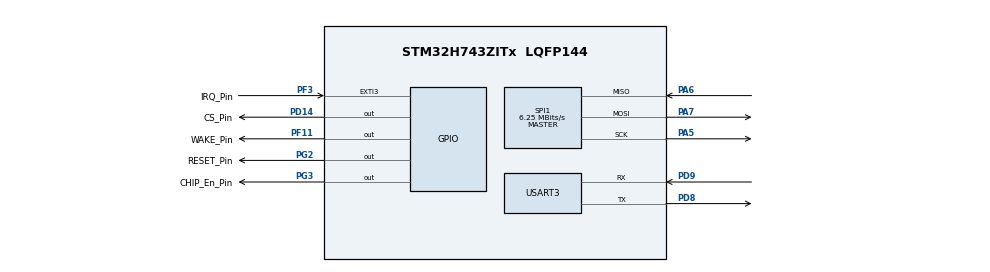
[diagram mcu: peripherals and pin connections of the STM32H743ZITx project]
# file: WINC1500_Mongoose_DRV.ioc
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CORTEX_M7.default_mode_Activation=1
Mcu.Family=STM32H7
Mcu.Name=STM32H743ZITx
Mcu.Package=LQFP144
NVIC.EXTI3_IRQn=true\:0\:0\:false\:false\:true\:true\:true\:true
NVIC.PriorityGroup=NVIC_PRIORITYGROUP_4
NVIC.TIM6_DAC_IRQn=true\:15\:0\:false\:false\:true\:false\:true\:true
NVIC.TimeBase=TIM6_DAC_IRQn
NVIC.TimeBaseIP=TIM6
PA5.GPIO_PuPd=GPIO_PULLUP
PA5.Mode=Full_Duplex_Master
PA5.Signal=SPI1_SCK
PA6.GPIO_PuPd=GPIO_PULLUP
PA6.Mode=Full_Duplex_Master
PA6.Signal=SPI1_MISO
PA7.GPIO_PuPd=GPIO_PULLUP
PA7.Mode=Full_Duplex_Master
PA7.Signal=SPI1_MOSI
PD14.GPIO_Label=CS_Pin
PD14.GPIO_PuPd=GPIO_PULLUP
PD14.Signal=GPIO_Output
PD8.Mode=Asynchronous
PD8.Signal=USART3_TX
PD9.Mode=Asynchronous
PD9.Signal=USART3_RX
PF11.GPIO_Label=WAKE_Pin
PF11.Signal=GPIO_Output
PF3.GPIO_Label=IRQ_Pin
PF3.GPIO_PuPd=GPIO_PULLUP
PF3.Signal=GPXTI3
PG2.GPIO_Label=RESET_Pin
PG2.GPIO_ModeDefaultOutputPP=GPIO_MODE_OUTPUT_PP
PG2.GPIO_PuPd=GPIO_PULLUP
PG2.Signal=GPIO_Output
PG3.GPIO_Label=CHIP_En_Pin
PG3.GPIO_PuPd=GPIO_PULLUP
PG3.Signal=GPIO_Output
ProjectManager.HeapSize=0x600
ProjectManager.StackSize=0x800
ProjectManager.TargetToolchain=STM32CubeIDE
RCC.ADCFreq_Value=129000000
RCC.APB1Freq_Value=100000000
RCC.APB2Freq_Value=100000000
RCC.APB3Freq_Value=100000000
RCC.APB4Freq_Value=100000000
RCC.CortexFreq_Value=400000000
RCC.D1PPRE=RCC_APB3_DIV2
RCC.D2PPRE1=RCC_APB1_DIV2
RCC.D2PPRE2=RCC_APB2_DIV2
RCC.D3PPRE=RCC_APB4_DIV2
RCC.DIVM1=4
RCC.DIVN1=50
RCC.DIVQ1=4
RCC.HCLKFreq_Value=200000000
RCC.HPRE=RCC_HCLK_DIV2
RCC.PLL2FRACN=0
RCC.PLL3FRACN=0
RCC.PLLFRACN=0
RCC.SYSCLKFreq_VALUE=400000000
RCC.SYSCLKSource=RCC_SYSCLKSOURCE_PLLCLK
RCC.USBFreq_Value=200000000
SPI1.BaudRatePrescaler=SPI_BAUDRATEPRESCALER_32
SPI1.CalculateBaudRate=6.25 MBits/s
SPI1.Direction=SPI_DIRECTION_2LINES
SPI1.Mode=SPI_MODE_MASTER
SPI1.VirtualType=VM_MASTER
USART3.VirtualMode-Asynchronous=VM_ASYNC
VP_MEMORYMAP_VS_MEMORYMAP.Mode=CurAppReg
VP_SYS_VS_tim6.Mode=TIM6
board=custom

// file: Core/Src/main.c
/* USER CODE BEGIN Header */
/**
  ******************************************************************************
  * @file           : main.c
  * @brief          : Main program body
  ******************************************************************************
  */
/* USER CODE END Header */

#include "main.h"
#include "spi.h"
#include "usart.h"
#include "gpio.h"

/* USER CODE BEGIN Includes */
#include <stdbool.h>
#include <string.h>
#include "m2m_wifi.h"
#include "conf_winc.h"
#include "socket.h"
#include "mongoose.h"
#include "winc_if.h"

/* USER CODE END Includes */

// Implementazione di gettimeofday
int _gettimeofday(struct timeval *tv, void *tzp) {
    (void)tzp;
    if (tv) {
        uint32_t tick = HAL_GetTick();
        tv->tv_sec = tick / 1000;
        tv->tv_usec = (tick % 1000) * 1000;
    }
    return 0;
}

void SystemClock_Config(void);
static void MPU_Config(void);
/* USER CODE BEGIN PFP */

static struct mg_mgr mgr;

// AGGIUNGI: definisci mg_millis come weak per evitare conflitti
__attribute__((weak)) uint64_t mg_millis(void) {
    return (uint64_t)HAL_GetTick();
}

#ifdef __GNUC__
#define PUTCHAR_PROTOTYPE int __io_putchar(int ch)
#else
#define PUTCHAR_PROTOTYPE int fputc(int ch, FILE *f)
#endif

extern void isr(void);

void HAL_GPIO_EXTI_Callback(uint16_t GPIO_Pin) {
    if (GPIO_Pin == CONF_WINC_SPI_INT_PIN) {
        isr();
    }
}

static void wifi_cb(uint8_t u8MsgType, void *pvMsg) {
    switch (u8MsgType) {
        case M2M_WIFI_RESP_CON_STATE_CHANGED: {
            tstrM2mWifiStateChanged *pstrWifiState = (tstrM2mWifiStateChanged *)pvMsg;
            if (pstrWifiState->u8CurrState == M2M_WIFI_CONNECTED) {
                printf("WiFi: Station connected\n");
            } else if (pstrWifiState->u8CurrState == M2M_WIFI_DISCONNECTED) {
                printf("WiFi: Station disconnected\n");
            }
            break;
        }
        case M2M_WIFI_REQ_DHCP_CONF: {
            uint8_t *pu8IPAddress = (uint8_t *)pvMsg;
            printf("WiFi: DHCP configured - IP: %u.%u.%u.%u\n",
                   pu8IPAddress[0], pu8IPAddress[1], pu8IPAddress[2], pu8IPAddress[3]);
            break;
        }
        default:
            break;
    }
}

PUTCHAR_PROTOTYPE {
    HAL_UART_Transmit(&huart3, (uint8_t *)&ch, 1, 0xFFFF);
    return ch;
}

int main(void) {
    tstrWifiInitParam param;
    tstrM2MAPConfig strM2MAPConfig;
    int8_t ret;

    // Inizializzazione HAL
    MPU_Config();
    HAL_Init();
    SystemClock_Config();
    MX_GPIO_Init();
    MX_SPI1_Init();
    MX_USART3_UART_Init();

    printf("\r\n--- STM32H7 + WINC1500 + Mongoose ---\r\n");

    // Inizializza WINC1500
    nm_bsp_init();
    registerSocketCallback(winc_sock_cb, NULL);

    memset(&param, 0, sizeof(param));
    param.pfAppWifiCb = wifi_cb;
    ret = m2m_wifi_init(&param);
    if (ret != M2M_SUCCESS) {
        printf("m2m_wifi_init failed: %d\n", ret);
        while(1);
    }

    // Configura AP mode
    memset(&strM2MAPConfig, 0, sizeof(strM2MAPConfig));
    strcpy((char *)&strM2MAPConfig.au8SSID, MAIN_WLAN_SSID);
    strM2MAPConfig.u8ListenChannel = MAIN_WLAN_CHANNEL;
    strM2MAPConfig.u8SecType = MAIN_WLAN_AUTH;
    strM2MAPConfig.au8DHCPServerIP[0] = 192;
    strM2MAPConfig.au8DHCPServerIP[1] = 168;
    strM2MAPConfig.au8DHCPServerIP[2] = 1;
    strM2MAPConfig.au8DHCPServerIP[3] = 1;

    ret = m2m_wifi_enable_ap(&strM2MAPConfig);
    if (ret != M2M_SUCCESS) {
        printf("m2m_wifi_enable_ap failed: %d\n", ret);
        while(1);
    }

    printf("AP mode started: %s\n", MAIN_WLAN_SSID);
    printf("Connect to http://192.168.1.1\n");

    // Inizializza Mongoose
    mg_mgr_init(&mgr);
    winc_if_init(&mgr);

    // Crea server HTTP
    if (!winc_create_http_server(80)) {
        printf("Failed to create HTTP server\n");
        while(1);
    }

    printf("HTTP server started on port 80\n");

    // Loop principale
    while (1) {
        winc_if_poll(&mgr, 10);
        mg_mgr_poll(&mgr, 0);  // Timeout 0 - solo processing interno
    }
}

void SystemClock_Config(void)
{
  RCC_OscInitTypeDef RCC_OscInitStruct = {0};
  RCC_ClkInitTypeDef RCC_ClkInitStruct = {0};

  /** Supply configuration update enable
  */
  HAL_PWREx_ConfigSupply(PWR_LDO_SUPPLY);

  /** Configure the main internal regulator output voltage
  */
  __HAL_PWR_VOLTAGESCALING_CONFIG(PWR_REGULATOR_VOLTAGE_SCALE1);

  while(!__HAL_PWR_GET_FLAG(PWR_FLAG_VOSRDY)) {}

  /** Initializes the RCC Oscillators according to the specified parameters
  * in the RCC_OscInitTypeDef structure.
  */
  RCC_OscInitStruct.OscillatorType = RCC_OSCILLATORTYPE_HSI;
  RCC_OscInitStruct.HSIState = RCC_HSI_DIV1;
  RCC_OscInitStruct.HSICalibrationValue = RCC_HSICALIBRATION_DEFAULT;
  RCC_OscInitStruct.PLL.PLLState = RCC_PLL_ON;
  RCC_OscInitStruct.PLL.PLLSource = RCC_PLLSOURCE_HSI;
  RCC_OscInitStruct.PLL.PLLM = 4;
  RCC_OscInitStruct.PLL.PLLN = 50;
  RCC_OscInitStruct.PLL.PLLP = 2;
  RCC_OscInitStruct.PLL.PLLQ = 4;
  RCC_OscInitStruct.PLL.PLLR = 2;
  RCC_OscInitStruct.PLL.PLLRGE = RCC_PLL1VCIRANGE_3;
  RCC_OscInitStruct.PLL.PLLVCOSEL = RCC_PLL1VCOWIDE;
  RCC_OscInitStruct.PLL.PLLFRACN = 0;
  if (HAL_RCC_OscConfig(&RCC_OscInitStruct) != HAL_OK)
  {
    Error_Handler();
  }

  /** Initializes the CPU, AHB and APB buses clocks
  */
  RCC_ClkInitStruct.ClockType = RCC_CLOCKTYPE_HCLK|RCC_CLOCKTYPE_SYSCLK
                              |RCC_CLOCKTYPE_PCLK1|RCC_CLOCKTYPE_PCLK2
                              |RCC_CLOCKTYPE_D3PCLK1|RCC_CLOCKTYPE_D1PCLK1;
  RCC_ClkInitStruct.SYSCLKSource = RCC_SYSCLKSOURCE_PLLCLK;
  RCC_ClkInitStruct.SYSCLKDivider = RCC_SYSCLK_DIV1;
  RCC_ClkInitStruct.AHBCLKDivider = RCC_HCLK_DIV2;
  RCC_ClkInitStruct.APB3CLKDivider = RCC_APB3_DIV2;
  RCC_ClkInitStruct.APB1CLKDivider = RCC_APB1_DIV2;
  RCC_ClkInitStruct.APB2CLKDivider = RCC_APB2_DIV2;
  RCC_ClkInitStruct.APB4CLKDivider = RCC_APB4_DIV2;

  if (HAL_RCC_ClockConfig(&RCC_ClkInitStruct, FLASH_LATENCY_2) != HAL_OK)
  {
    Error_Handler();
  }
}

 /* MPU Configuration */

void MPU_Config(void)
{
  MPU_Region_InitTypeDef MPU_InitStruct = {0};

  /* Disables the MPU */
  HAL_MPU_Disable();

  /** Initializes and configures the Region and the memory to be protected
  */
  MPU_InitStruct.Enable = MPU_REGION_ENABLE;
  MPU_InitStruct.Number = MPU_REGION_NUMBER0;
  MPU_InitStruct.BaseAddress = 0x0;
  MPU_InitStruct.Size = MPU_REGION_SIZE_4GB;
  MPU_InitStruct.SubRegionDisable = 0x87;
  MPU_InitStruct.TypeExtField = MPU_TEX_LEVEL0;
  MPU_InitStruct.AccessPermission = MPU_REGION_NO_ACCESS;
  MPU_InitStruct.DisableExec = MPU_INSTRUCTION_ACCESS_DISABLE;
  MPU_InitStruct.IsShareable = MPU_ACCESS_SHAREABLE;
  MPU_InitStruct.IsCacheable = MPU_ACCESS_NOT_CACHEABLE;
  MPU_InitStruct.IsBufferable = MPU_ACCESS_NOT_BUFFERABLE;

  HAL_MPU_ConfigRegion(&MPU_InitStruct);
  /* Enables the MPU */
  HAL_MPU_Enable(MPU_PRIVILEGED_DEFAULT);

}

void HAL_TIM_PeriodElapsedCallback(TIM_HandleTypeDef *htim)
{
  if (htim->Instance == TIM6)
  {
    HAL_IncTick();
  }
}

void Error_Handler(void)
{
  __disable_irq();
  while (1)
  {
  }
}
